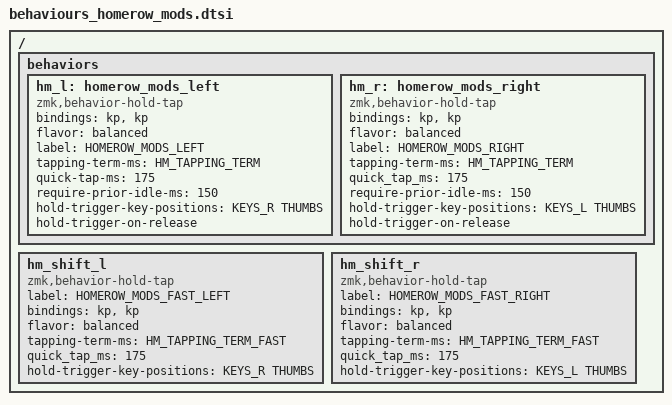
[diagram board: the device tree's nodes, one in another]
// from https://github.com/urob/zmk-config#timeless-homerow-mods
// and https://github.com/infused-kim/zmk-config/blob/chocofi/main/config/includes/settings.dtsi

#define KEYS_L 0 1 2 3 4 10 11 12 13 14 20 21 22 23 24  // left-hand keys
#define KEYS_R 5 6 7 8 9 15 16 17 18 19 25 26 27 28 29  // right-hand keys
#define THUMBS 30 31 32 33 34 35                        // thumb keys

#define HM_TAPPING_TERM 350             // ms in case you want to trigger Modifier on the same side
#define HM_TAPPING_TERM_FAST 200        // separate term for Shift activation


/ {

   behaviors {
        // Positional Homerow mods
        // Homerow mods that prevent accidental activations when rolling keys,
        // such as when typing `st` or `ne` on colemak-dh layouts or `as` on
        // qwerty.
        //
        // Works by only allowing a mod to activate within tapping-term if
        // it's on the opposite side of the keyboard or on the same side thumb
        // keys.

                hm_l: homerow_mods_left {
                compatible = "zmk,behavior-hold-tap";
                bindings = <&kp>,  <&kp>;
                #binding-cells = <2>;
                flavor = "balanced";
                label = "HOMEROW_MODS_LEFT";
                tapping-term-ms = <HM_TAPPING_TERM>;
                quick-tap-ms = <175>;
                require-prior-idle-ms = <150>;
                hold-trigger-key-positions = <KEYS_R THUMBS>;
                hold-trigger-on-release;             
                };

                hm_r: homerow_mods_right {
                compatible = "zmk,behavior-hold-tap";
                bindings = <&kp>, <&kp>;
                #binding-cells = <2>;
                flavor = "balanced";
                label = "HOMEROW_MODS_RIGHT";
                tapping-term-ms = <HM_TAPPING_TERM>;
                quick_tap_ms = <175>; 
                require-prior-idle-ms = <150>; 
                hold-trigger-key-positions = <KEYS_L THUMBS>;
                hold-trigger-on-release;         
                };
        };

        // Positional Homerow mods for shift
        // Use faster tapping term and disable some features that may
        // cause false negatives.
        hm_shift_l: hm_shift_l {
            compatible = "zmk,behavior-hold-tap";
            label = "HOMEROW_MODS_FAST_LEFT";
            #binding-cells = <2>;
            bindings = <&kp>, <&kp>;

            flavor = "balanced";
            tapping-term-ms = <HM_TAPPING_TERM_FAST>;
            quick_tap_ms = <175>;
            // global-quick-tap-ms = <150>;         // requires PR #1387
            hold-trigger-key-positions = <KEYS_R THUMBS>;
            // hold-trigger-on-release;             // requires PR #1423
        };

        hm_shift_r: hm_shift_r {
            compatible = "zmk,behavior-hold-tap";
            label = "HOMEROW_MODS_FAST_RIGHT";
            #binding-cells = <2>;
            bindings = <&kp>, <&kp>;

            flavor = "balanced";
            tapping-term-ms = <HM_TAPPING_TERM_FAST>;
            quick_tap_ms = <175>;
            // global-quick-tap-ms = <150>;         // requires PR #1387
            hold-trigger-key-positions = <KEYS_L THUMBS>;
            // hold-trigger-on-release;             // requires PR #1423
        };


    
};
